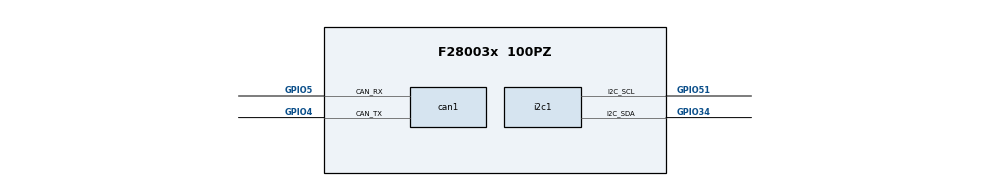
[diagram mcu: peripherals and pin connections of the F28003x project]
/**
 * @cliArgs --device "F28003x" --part "F28003x_100PZ" --package "100PZ" --context "system" --product "C2000WARE@5.03.00.00"
 * @versions {"tool":"1.21.0+3721"}
 */

/**
 * Import the modules used in this configuration.
 */
const can       = scripting.addModule("/driverlib/can.js", {}, false);
const can1      = can.addInstance();
const cputimer  = scripting.addModule("/driverlib/cputimer.js", {}, false);
const cputimer1 = cputimer.addInstance();
const i2c       = scripting.addModule("/driverlib/i2c.js", {}, false);
const i2c1      = i2c.addInstance();

/**
 * Write custom configuration values to the imported modules.
 */
can1.$name                 = "CAN0";
can1.msgObjsUsed           = [1];
can1.can.can_rxPin.$assign = "GPIO5";
can1.can.can_txPin.$assign = "GPIO4";
can1.msgObj1.$name         = "msgObj0";
can1.msgObj1.msgType       = "CAN_MSG_OBJ_TYPE_TX";
can1.msgObj1.msgLen        = 8;
can1.msgObj1.msgID         = 291;

cputimer1.$name                    = "mainTimer";
cputimer1.emulationMode            = "CPUTIMER_EMULATIONMODE_RUNFREE";
cputimer1.enableInterrupt          = true;
cputimer1.registerInterrupts       = true;
cputimer1.startTimer               = true;
cputimer1.timerPeriod              = 120000;
cputimer1.timerInt.enableInterrupt = true;

i2c1.$name                  = "encoder_I2C";
i2c1.emulationMode          = "I2C_EMULATION_FREE_RUN";
i2c1.bitCount               = "I2C_BITCOUNT_8";
i2c1.enabledInterrupts      = ["I2C_INT_REG_ACCESS_RDY","I2C_INT_STOP_CONDITION"];
i2c1.registerInterrupts     = true;
i2c1.useFifo                = false;
i2c1.i2c.$assign            = "I2CB";
i2c1.i2c.i2c_sdaPin.$assign = "GPIO34";
i2c1.i2c.i2c_sclPin.$assign = "GPIO51";
i2c1.sdaQual.padConfig      = "STD";
i2c1.sclQual.padConfig      = "STD";

/**
 * Pinmux solution for unlocked pins/peripherals. This ensures that minor changes to the automatic solver in a future
 * version of the tool will not impact the pinmux you originally saw.  These lines can be completely deleted in order to
 * re-solve from scratch.
 */
can1.can.$suggestSolution = "CANA";
